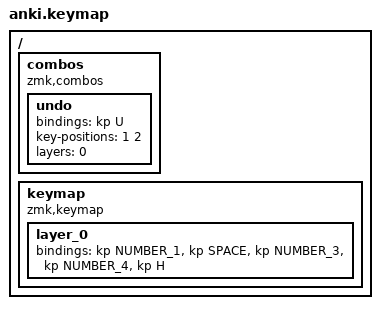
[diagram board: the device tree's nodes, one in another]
#include <behaviors.dtsi>
#include <dt-bindings/zmk/keys.h>

/ {
    combos {
        compatible = "zmk,combos";

        undo {
            bindings = <&kp U>;
            key-positions = <1 2>;
            layers = <0>;
        };
    };

    keymap {
        compatible = "zmk,keymap";

        layer_0 {
            bindings = <
&kp NUMBER_1  &kp SPACE  &kp NUMBER_3  &kp NUMBER_4  &kp H
            >;
        };
    };
};
